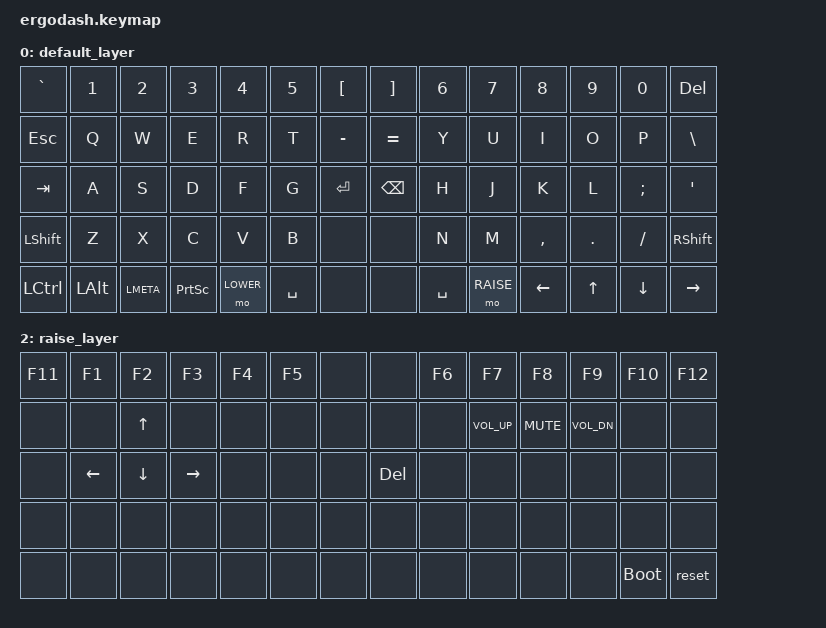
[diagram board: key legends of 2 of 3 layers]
/*
 * Copyright (c) 2020 The ZMK Contributors
 *
 * SPDX-License-Identifier: MIT
 */

#include <behaviors.dtsi>
#include <dt-bindings/zmk/keys.h>
#include <dt-bindings/zmk/bt.h>
#include <dt-bindings/zmk/ext_power.h>
#include <dt-bindings/zmk/outputs.h>

#define DEFAULT 0
#define LOWER   1
#define RAISE   2


/ {
        keymap {
                compatible = "zmk,keymap";

                default_layer {
/* QWERTY
 * .----------------------------------------------------------------------------------------------------------------------.
 * |  `   |   1  |   2  |   3  |   4  |   5  |  [   |                    |  ]   |   6  |   7  |   8  |   9  |   0  |  DEL |
 * |------+------+------+------+------+------+------+--------------------+------+------+------+------+------+------+------|
 * | ESC  |   Q  |   W  |   E  |   R  |   T  |  -   |                    |  =   |   Y  |   U  |   I  |   O  |   P  |  \   |
 * |------+------+------+------+------+------+------+--------------------+------+------+------+------+------+------+------|
 * | Tab  |   A  |   S  |   D  |   F  |   G  | Enter|                    | Bksp |   H  |   J  |   K  |   L  |   ;  |  '   |
 * |------+------+------+------+------+------+---------------------------+------+------+------+------+------+------+------|
 * | Shift|   Z  |   X  |   C  |   V  |   B  | ???? |                    | ???? |   N  |   M  |   ,  |   .  |   /  | Shift|
 * |-------------+------+------+------+------+------+------+------+------+------+------+------+------+------+-------------|
 * | Ctrl |  Alt |  Win | PScr |||||||| Lower| Space| ???  |||||||| ???? | Space| Raise|||||||| Left |   Up | Down | Right|
 * .----------------------------------------------------------------------------------------------------------------------.
 */
                        bindings = <
&kp  GRAVE    &kp  N1       &kp  N2       &kp  N3       &kp  N4       &kp  N5       &kp  LBKT              &kp  RBKT     &kp  N6       &kp  N7       &kp  N8       &kp  N9       &kp  N0       &kp  DEL
&kp  ESC      &kp  Q        &kp  W        &kp  E        &kp  R        &kp  T        &kp  MINUS             &kp  EQUAL    &kp  Y        &kp  U        &kp  I        &kp  O        &kp  P        &kp  BSLH
&kp  TAB      &kp  A        &kp  S        &kp  D        &kp  F        &kp  G        &kp  RET               &kp  BSPC     &kp  H        &kp  J        &kp  K        &kp  L        &kp  SEMI     &kp  SQT
&kp  LSHFT    &kp  Z        &kp  X        &kp  C        &kp  V        &kp  B        &none                  &none         &kp  N        &kp  M        &kp  COMMA    &kp  DOT      &kp  SLASH    &kp  RSHFT
&kp  LCTRL    &kp  LALT     &kp  LMETA    &kp  PSCRN    &mo  LOWER    &kp  SPACE    &none                  &none         &kp  SPACE    &mo  RAISE    &kp  LEFT     &kp  UP       &kp  DOWN     &kp  RIGHT
                        >;
                };
                lower_layer {
/* .----------------------------------------------------------------------------------------------------------------------.
 * |  F11 |  F1  |  F2  |  F3  |  F4  |  F5  |      |                    |      |  F6  |  F7  |  F8  |  F9  |  F10 |  F12 |
 * |------+------+------+------+------+------+------+--------------------+------+------+------+------+------+------+------|
 * |      | EP_ON|EP_OFF|      |  USB |  BLE |      |                    |      |      |      |      |      |      |      |
 * |------+------+------+------+------+------+------+--------------------+------+------+------+------+------+------+------|
 * |      | BTP0 | BTP1 | BTP2 | BTP3 | BTP4 |      |                    |      |      |      |      |      |      |      |
 * |------+------+------+------+------+------+---------------------------+------+------+------+------+------+------+------|
 * |      |      |      |      |      |      |      |                    |      |      |      |      |      |      |      |
 * |-------------+------+------+------+------+------+------+------+------+------+------+------+------+------+-------------|
 * | REST | BOOT | BTPR |      |      |      |      |      |      |      |      |      |      | HOME | PGUP | PGDN |  END |
 * .----------------------------------------------------------------------------------------------------------------------.
 */
                        bindings = <
&kp  F11      &kp  F1       &kp  F2       &kp  F3       &kp  F4       &kp  F5       &kp  &none             &kp  &none    &kp  F6       &kp  F7       &kp  F8       &kp  F9       &kp  F10      &kp  F12
&none         &ext_power  EP_OFF &ext_power  EP_ON &none &out OUT_USB &out OUT_BLE  &none                  &none         &none         &none         &none         &none         &none         &none
&none         &bt  BT_SEL 0 &bt  BT_SEL 1 &bt  BT_SEL 2 &bt  BT_SEL 3 &bt  BT_SEL 4 &none                  &none         &none         &none         &none         &none         &none         &none
&none         &none         &none         &none         &none         &none         &none                  &none         &none         &none         &none         &none         &none         &none
&reset        &bootloader   &bt  BT_CLR   &none         &none         &none         &none                  &none         &none         &none         &kp  HOME     &kp  PG_UP    &kp  PG_DN    &kp  END
                        >;
                };
                raise_layer {
/* .----------------------------------------------------------------------------------------------------------------------.
 * |  F11 |  F1  |  F2  |  F3  |  F4  |  F5  |      |                    |      |  F6  |  F7  |  F8  |  F9  |  F10 |  F12 |
 * |------+------+------+------+------+------+------+--------------------+------+------+------+------+------+------+------|
 * |      |      |  UP  |      |      |      |      |                    |      |      |VOLDWN| VOLM | VOLUP|      |      |
 * |------+------+------+------+------+------+------+--------------------+------+------+------+------+------+------+------|
 * |      | Left | Down | Right|      |      |      |                    |  DEL |      |      |      |      |      |      |
 * |------+------+------+------+------+------+---------------------------+------+------+------+------+------+------+------|
 * |      |      |      |      |      |      |      |                    |      |      |      |      |      |      |      |
 * |-------------+------+------+------+------+------+------+------+------+------+------+------+------+------+-------------|
 * |      |      |      |      |      |      |      |      |      |      |      |      |      |      |      | BOOT | REST |
 * .----------------------------------------------------------------------------------------------------------------------.
 */
                        bindings = <
&kp  F11      &kp  F1       &kp  F2       &kp  F3       &kp  F4       &kp  F5       &none                  &none         &kp  F6       &kp  F7       &kp  F8       &kp  F9       &kp  F10      &kp  F12
&none         &none         &kp  UP       &none         &none         &none         &none                  &none         &none         &kp  C_VOL_UP &kp  C_MUTE   &kp  C_VOL_DN &none         &none
&none         &kp  LEFT     &kp  DOWN     &kp  RIGHT    &none         &none         &none                  &kp  DEL      &none         &none         &none         &none         &none         &none
&none         &none         &none         &none         &none         &none         &none                  &none         &none         &none         &none         &none         &none         &none
&none         &none         &none         &none         &none         &none         &none                  &none         &none         &none         &none         &none         &bootloader   &reset
                        >;
                };
        };
};
